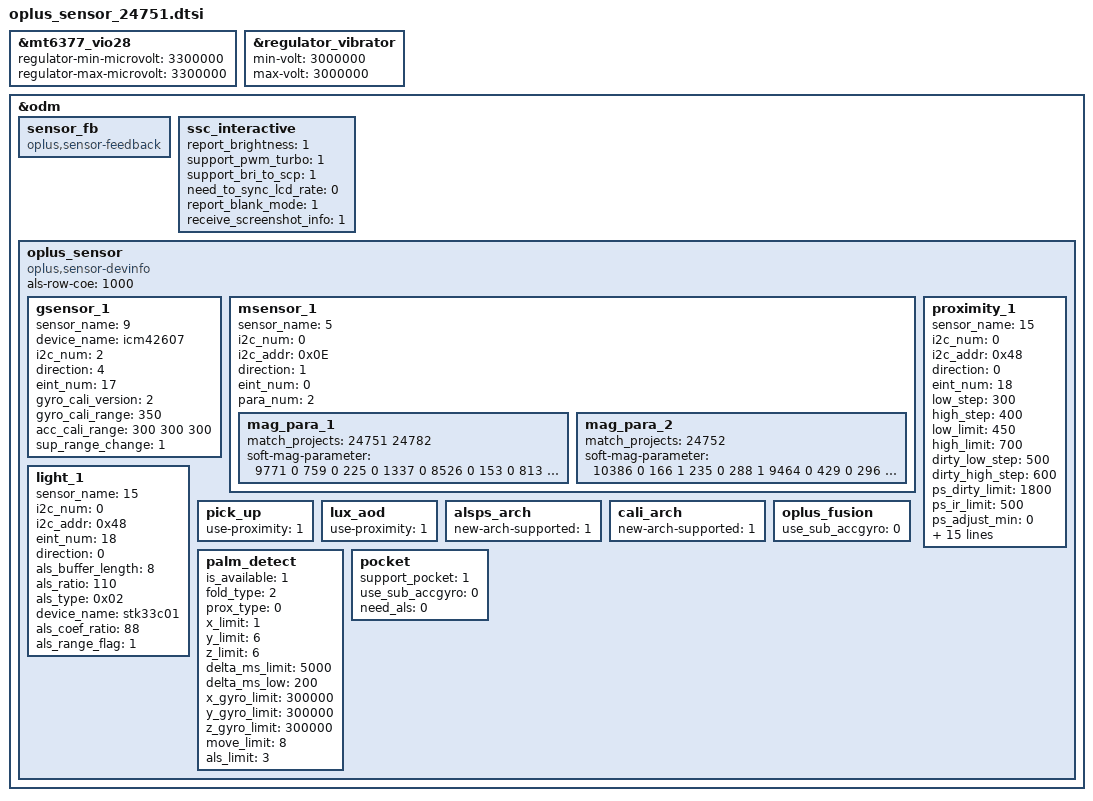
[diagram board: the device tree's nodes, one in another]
&mt6377_vio28 {
	regulator-min-microvolt = <3300000>;
	regulator-max-microvolt = <3300000>;
};
&regulator_vibrator{
	min-volt = <3000000>;
	max-volt = <3000000>;
};

&odm {
	sensor_fb: sensor_fb {
		compatible = "oplus,sensor-feedback";
	};
	ssc_interactive: ssc_interactive {
		report_brightness = <1>;
		support_pwm_turbo = <1>;
		support_bri_to_scp = <1>;
		need_to_sync_lcd_rate = <0>;
		report_blank_mode = <1>;
		receive_screenshot_info = <1>;
	};
	oplus_sensor:oplus_sensor {
		compatible = "oplus,sensor-devinfo";
		als-row-coe = <1000>;
		/* sensor start */
		/*
		enum {
			LIS3DH,
			LSM6DS3,
			BMI160,
			LIS2HH12,
			LSM6DSM,
			BMI2XY,
			LSM6DSO,
			ICM4X6XX,
			ICM4263X,
			ICM4N607,
			BMI22X,
			SC7A20,
			MC34X9,
		};
		*/
		gsensor_1: gsensor_1 {
			status = "okay";
			sensor_name = <9>; // ICM4N607
			device_name = "icm42607";
			i2c_num = <2>;
			direction = <4>;
			eint_num = <17>;
			gyro_cali_version= <2>;
			gyro_cali_range =<350>;
			acc_cali_range= <300 300 300>;
			sup_range_change = <1>;
		};

		/*
		enum {
			AKM09911,
			MMC3530,
			MMC5603,
			MXG4300,
			AKM09918,
			AKM09919,
		};
		*/
		msensor_1: msensor_1 {
			status = "okay";
			sensor_name = <5>; // AKM09919
			i2c_num = <0>;
			i2c_addr = <0x0E>;
			direction = <1>;
			eint_num = <0>;
			para_num = <2>;
			mag_para_1 {
				match_projects = <24751 24782>;
				soft-mag-parameter = <9771 0 759 0 225 0 1337 0 8526 0 153 0 813 0 199 1 11256 0>;
			};
			mag_para_2 {
				match_projects = <24752>;
				soft-mag-parameter = <10386 0 166 1 235 0 288 1 9464 0 429 0 296 0 249 0 11644 0>;
			};
		};
		/*
		enum {
			TMD2725,
			APSD9922,
			STK3335,
			STK3331,
			STK2232,
			TCS3701,
			STK32600,
			STK33502,
			MN78911,
			TCS3720,
			SIP3515,
			STK3329,
			LTR569,
			SIP3510,
			SIP3625,
		};
		*/
		proximity_1: proximity_1 {
			status = "okay";
			sensor_name = <15>; // STK33C01
			i2c_num = <0>;
			i2c_addr = <0x48>;
			direction = <0>;
			eint_num = <18>;
			low_step = <300>;
			high_step = <400>;
			low_limit = <450>;
			high_limit = <700>;
			dirty_low_step = <500>;
			dirty_high_step = <600>;
			ps_dirty_limit = <1800>;
			ps_ir_limit = <500>;
			ps_adjust_min = <0>;
			ps_adjust_max = <1850>;
			sampling_count = <5>;
			step_max = <500>;
			step_min = <100>;
			step_div = <2000>;
			anti_shake_delta = <120>;
			dynamic_cali_max = <3000>;
			raw2offset_radio = <1000>;
			offset_max = <15000>;
			offset_range_min = <0>;
			offset_range_max = <65535>;
			force_cali_limit = <2000>;
			cali_jitter_limit = <40>;
			cal_offset_margin = <3000>;
			sensor-reg = <0x01 0x44 0x03 0x5C 0x05 0x41>;
		};
		light_1: light_1 {
			status = "okay";
			sensor_name = <15>; // STK33C01
			i2c_num = <0>;
			i2c_addr = <0x48>;
			eint_num = <18>;
			direction = <0>;
			als_buffer_length =<8>;
			als_ratio = <110>;
			als_type = <0x02>; //0x01 CCT_NORMAL 0x02 CCT_WISE
			device_name = "stk33c01";
			als_coef_ratio = <88>;
			als_range_flag = <1>;
		};
		pick_up: pick_up {
			status = "okay";
			use-proximity = <1>;
		};
		lux_aod: lux_aod {
			status = "okay";
			use-proximity = <1>;
		};
		alsps_arch: alsps_arch {
			status = "okay";
			new-arch-supported = <1>;
		};
		cali_arch: cali_arch {
			status = "okay";
			new-arch-supported = <1>;
		};
		oplus_fusion: oplus_fusion {
			status = "okay";
			use_sub_accgyro = <0>;
		};
		palm_detect: palm_detect{
			status = "okay";
			is_available = <1>;
			fold_type = <2>;
			prox_type = <0>;
			x_limit = <1>;
			y_limit = <6>;
			z_limit = <6>;
			delta_ms_limit = <5000>;
			delta_ms_low = <200>;
			x_gyro_limit = <300000>;
			y_gyro_limit = <300000>;
			z_gyro_limit = <300000>;
			move_limit = <8>;
			als_limit = <3>;
		};
		pocket: pocket {
			status = "okay";
			support_pocket = <1>;
			use_sub_accgyro = <0>;
			need_als = <0>;
		};
	};
/* sensor end */
};
